AUTOSAR XML (schema 4-3-0)
package /Dimmer
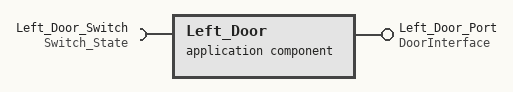
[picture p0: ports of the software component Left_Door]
  application sw component type Left_Door
    require port Left_Door_Switch: client-com-spec=getSwitchState, required-interface=Switch_State
    provide port Left_Door_Port: nonqueued-sender-com-spec=DoorStatus, provided-interface=DoorInterface
    behavior Left_Door_InternalBehavior
  swc implementation Left_Door_Implementation: behavior=Left_Door_InternalBehavior
